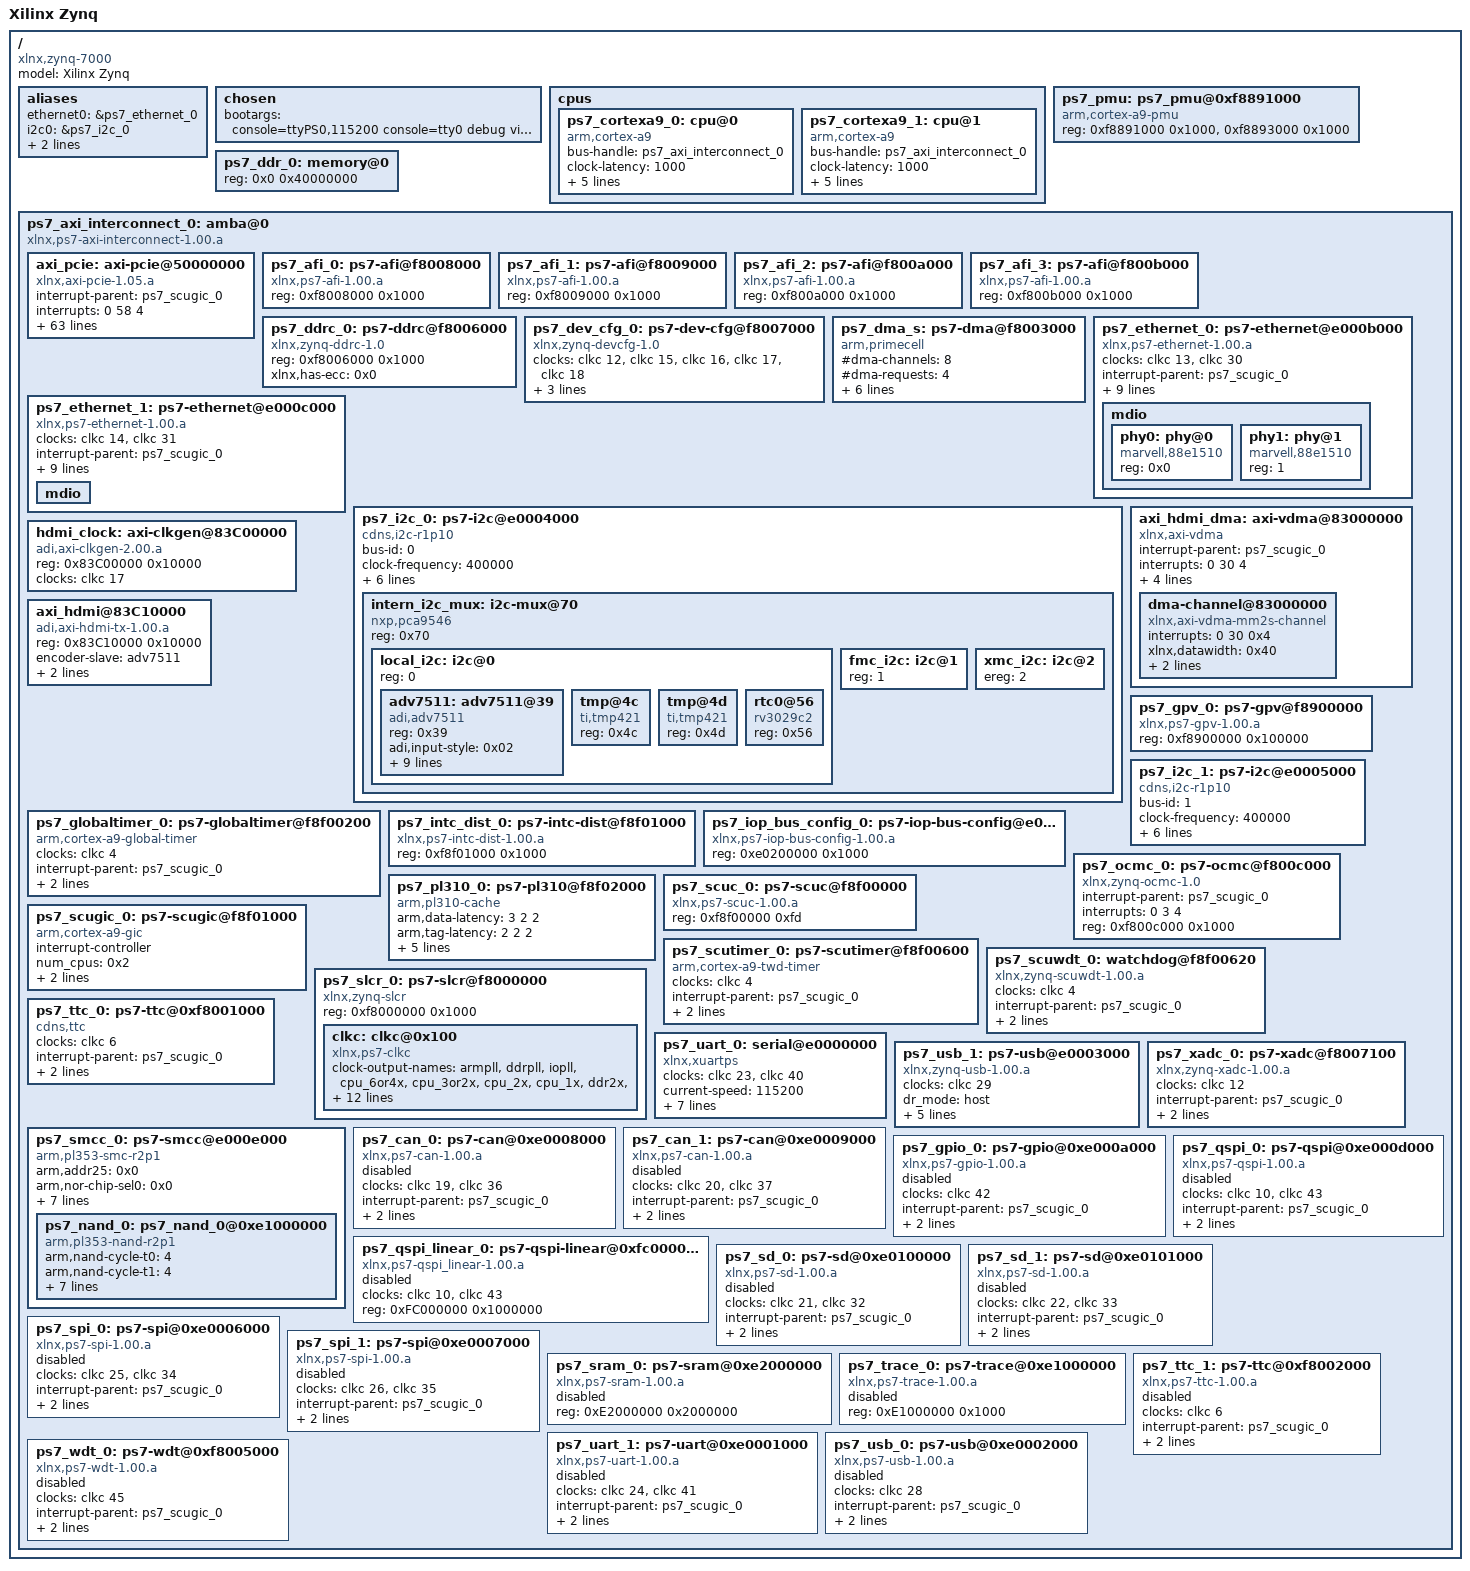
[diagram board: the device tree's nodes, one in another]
/*
 *  ApisSys AV108 Device Tree
 *  2014.2 Release 
 *
 */

/dts-v1/;
/ {
	#address-cells = <1>;
	#size-cells = <1>;
	compatible = "xlnx,zynq-7000";
	model = "Xilinx Zynq";
	aliases {
		ethernet0 = &ps7_ethernet_0;
		/*ethernet1 = &ps7_ethernet_1;*/
		i2c0 = &ps7_i2c_0;
		i2c1 = &ps7_i2c_1;
		serial0 = &ps7_uart_0;
	} ;
	chosen {
	    bootargs = "console=ttyPS0,115200 console=tty0 debug video=HDMI-A-1:1920x1080 vmalloc=384M root=/dev/ram rw ip=:::::eth0:dhcp earlyprintk ;linux,stdout-path =  /amba@0/serial@e0000000 ;";
	};

	cpus {
		#address-cells = <0x1>;
		#size-cells = <0x0>;
		ps7_cortexa9_0: cpu@0 {
			bus-handle = <&ps7_axi_interconnect_0>;
			clock-latency = <1000>;
			clocks = <&clkc 3>;
			compatible = "arm,cortex-a9";
			device_type = "cpu";
			interrupt-handle = <&ps7_scugic_0>;
			operating-points = <666667 1000000 333334 1000000 222223 1000000>;
			reg = <0x0>;
		};

		ps7_cortexa9_1: cpu@1 {
			bus-handle = <&ps7_axi_interconnect_0>;
			clock-latency = <1000>;
			clocks = <&clkc 3>;
			compatible = "arm,cortex-a9";
			device_type = "cpu";
			interrupt-handle = <&ps7_scugic_0>;
			operating-points = <666667 1000000 333334 1000000 222223 1000000>;
			reg = <0x1>;
		};
	};

	ps7_pmu: ps7_pmu@0xf8891000 {
		compatible = "arm,cortex-a9-pmu";
		reg = <0xf8891000 0x1000>, <0xf8893000 0x1000>;
		reg-names = "cpu0", "cpu1";
	};
	ps7_ddr_0: memory@0 {
		device_type = "memory";
		reg = <0x0 0x40000000>;
	};
	ps7_axi_interconnect_0: amba@0 {
		#address-cells = <0x1>;
		#size-cells = <0x1>;
		compatible = "xlnx,ps7-axi-interconnect-1.00.a", "simple-bus";
		ranges;
		linux,phandle = <0x1>;
		phandle = <0x1>;

		axi_pcie: axi-pcie@50000000 {
			#address-cells = <3>;		// Added from previous dts 
			#size-cells = <2>;		// Addes from previous dts 
			compatible = "xlnx,axi-pcie-1.05.a";
			ranges = <0x2000000 0x0 0x60000000 0x60000000 0x0 0x10000000>; // Added from previous dts 
			interrupt-parent = <&ps7_scugic_0>;
			interrupts = <0 58 4>;
			reg = <0x50000000 0x1000000>;
			//, <0x60000000 0x10000000>;
			xlnx,axibar-0 = <0x60000000>;
			xlnx,axibar-1 = <0xFFFFFFFF>;
			xlnx,axibar-2 = <0xFFFFFFFF>;
			xlnx,axibar-3 = <0xFFFFFFFF>;
			xlnx,axibar-4 = <0xFFFFFFFF>;
			xlnx,axibar-5 = <0xFFFFFFFF>;
			xlnx,axibar-as-0 = <0x0>;
			xlnx,axibar-as-1 = <0x0>;
			xlnx,axibar-as-2 = <0x0>;
			xlnx,axibar-as-3 = <0x0>;
			xlnx,axibar-as-4 = <0x0>;
			xlnx,axibar-as-5 = <0x0>;
			xlnx,axibar-highaddr-0 = <0x6FFFFFFF>;
			xlnx,axibar-highaddr-1 = <0x00000000>;
			xlnx,axibar-highaddr-2 = <0x00000000>;
			xlnx,axibar-highaddr-3 = <0x00000000>;
			xlnx,axibar-highaddr-4 = <0x00000000>;
			xlnx,axibar-highaddr-5 = <0x00000000>;
			xlnx,axibar-num = <0x1>;
			xlnx,axibar2pciebar-0 = <0x60000000>;
			xlnx,axibar2pciebar-1 = <0x00000000>;
			xlnx,axibar2pciebar-2 = <0x00000000>;
			xlnx,axibar2pciebar-3 = <0x00000000>;
			xlnx,axibar2pciebar-4 = <0x00000000>;
			xlnx,axibar2pciebar-5 = <0x00000000>;
			xlnx,class-code = <0x060400>;
			xlnx,comp-timeout = <0x1>;
			xlnx,device = "xc7z045";
			xlnx,device-id = <0x0706>;
			xlnx,include-baroffset-reg = <0x1>;
			xlnx,include-rc = <0x1>;
			xlnx,interrupt-pin = <0x0>;
			xlnx,max-link-speed = <0x0>;
			xlnx,no-of-lanes = <0x4>;
			xlnx,num-msi-req = <0x0>;
			xlnx,pcie-blk-locn = <0x0>;
			xlnx,pcie-cap-slot-implemented = <0x0>;
			xlnx,pcie-use-mode = "3.0";
			xlnx,pciebar-as = <0x0>;
			xlnx,pciebar-len-0 = <0x1e>;
			xlnx,pciebar-len-1 = <0x10>;
			xlnx,pciebar-len-2 = <0x10>;
			xlnx,pciebar-num = <0x1>;
			xlnx,pciebar2axibar-0 = <0x00000000>;
			xlnx,pciebar2axibar-0-sec = <0x1>;
			xlnx,pciebar2axibar-1 = <0xFFFFFFFF>;
			xlnx,pciebar2axibar-1-sec = <0x1>;
			xlnx,pciebar2axibar-2 = <0xFFFFFFFF>;
			xlnx,pciebar2axibar-2-sec = <0x1>;
			xlnx,ref-clk-freq = <0x0>;
			xlnx,rev-id = <0x0>;
			xlnx,s-axi-ctl-aclk-freq-hz = <0x7735940>;
			xlnx,s-axi-ctl-protocol = "AXI4LITE";
			xlnx,s-axi-id-width = <0xc>;
			xlnx,s-axi-support-threads = <0x1>;
			xlnx,s-axi-supports-narrow-burst = <0x1>;
			xlnx,s-axi-supports-read = <0x1>;
			xlnx,s-axi-supports-write = <0x1>;
			xlnx,subsystem-id = <0x0007>;
			xlnx,subsystem-vendor-id = <0x10EE>;
			xlnx,vendor-id = <0x10EE>;
			xlnx,xlnx-ref-board = "NONE";
		} ;


		ps7_afi_0: ps7-afi@f8008000 {
			compatible = "xlnx,ps7-afi-1.00.a";
			reg = <0xf8008000 0x1000>;
		};

		ps7_afi_1: ps7-afi@f8009000 {
			compatible = "xlnx,ps7-afi-1.00.a";
			reg = <0xf8009000 0x1000>;
		};

		ps7_afi_2: ps7-afi@f800a000 {
			compatible = "xlnx,ps7-afi-1.00.a";
			reg = <0xf800a000 0x1000>;
		};

		ps7_afi_3: ps7-afi@f800b000 {
			compatible = "xlnx,ps7-afi-1.00.a";
			reg = <0xf800b000 0x1000>;
		};

/*
		ps7_coresight_comp_0: ps7-coresight-comp@f8800000 {
			compatible = "xlnx,ps7-coresight-comp-1.00.a";
			reg = <0xf8800000 0x100000>;
		};
*/

		ps7_ddrc_0: ps7-ddrc@f8006000 {
			compatible = "xlnx,zynq-ddrc-1.0";
			reg = <0xf8006000 0x1000>;
			xlnx,has-ecc = <0x0>;
		};
		ps7_dev_cfg_0: ps7-dev-cfg@f8007000 {
			clock-names = "ref_clk", "fclk0", "fclk1", "fclk2", "fclk3";
			clocks = <&clkc 12>, <&clkc 15>, <&clkc 16>, <&clkc 17>, <&clkc 18>;
			compatible = "xlnx,zynq-devcfg-1.0";
			interrupt-parent = <&ps7_scugic_0>;
			interrupts = <0 8 4>;
			reg = <0xf8007000 0x100>;
		};

		ps7_dma_s: ps7-dma@f8003000 {
			#dma-cells = <1>;
			#dma-channels = <8>;
			#dma-requests = <4>;
			arm,primecell-periphid = <0x00041330>;
			clock-names = "apb_pclk";
			clocks = <&clkc 27>;
			compatible = "arm,primecell", "arm,pl330";
			interrupt-names = "abort", "dma0", "dma1", "dma2", "dma3", "dma4", "dma5", "dma6", "dma7";
			interrupt-parent = <&ps7_scugic_0>;
			interrupts = <0 13 4>, <0 14 4>, <0 15 4>, <0 16 4>, <0 17 4>, <0 40 4>, <0 41 4>, <0 42 4>, <0 43 4>;
			reg = <0xf8003000 0x1000>;
		};

		ps7_ethernet_0: ps7-ethernet@e000b000 {
			#address-cells = <1>;
			#size-cells = <0>;
			clock-names = "ref_clk", "aper_clk";
			clocks = <&clkc 13>, <&clkc 30>;
			compatible = "xlnx,ps7-ethernet-1.00.a";
			interrupt-parent = <&ps7_scugic_0>;
			interrupts = <0 22 4>;
			local-mac-address = [00 0a 35 00 00 00];
			phy-handle = <&phy0>;
			phy-mode = "rgmii-id";
			reg = <0xe000b000 0x1000>;
			xlnx,ptp-enet-clock = <0x69f6bcb>;
			xlnx,enet-reset = "";
			xlnx,eth-mode = <0x1>;
			xlnx,has-mdio = <0x1>;
			mdio {
				#address-cells = <1>;
				#size-cells = <0>;
				phy0: phy@0 {
					compatible = "marvell,88e1510";
					device_type = "ethernet-phy";
					reg = <0x0>;
				};
				
				phy1: phy@1 {
					compatible = "marvell,88e1510";
					device_type = "ethernet-phy";
					reg = <1>;
				} ;
				
			};
		};


		ps7_ethernet_1: ps7-ethernet@e000c000 {
			#address-cells = <1>;
			#size-cells = <0>;
			clock-names = "ref_clk", "aper_clk";
			clocks = <&clkc 14>, <&clkc 31>;
			compatible = "xlnx,ps7-ethernet-1.00.a";
			interrupt-parent = <&ps7_scugic_0>;
			interrupts = <0 45 4>;
			local-mac-address = [00 0a 35 00 00 01];
			phy-handle = <&phy1>;
			phy-mode = "rgmii-id";
			reg = <0xe000c000 0x1000>;
			xlnx,ptp-enet-clock = <0x69f6bcb>;
			xlnx,enet-reset = "<Select>";
			xlnx,eth-mode = <0x1>;
			xlnx,has-mdio = <0x0>;
			mdio {
				#address-cells = <1>;
				#size-cells = <0>;
			} ;
		} ;


		ps7_i2c_0: ps7-i2c@e0004000 {
			bus-id = <0>;
			clock-frequency = <400000>;
			clocks = <&clkc 38>;
			compatible = "cdns,i2c-r1p10";
			interrupt-parent = <&ps7_scugic_0>;
			interrupts = <0 25 4>;
			reg = <0xe0004000 0x1000>;
			xlnx,has-interrupt = <0x1>;
			xlnx,i2c-reset = "";
			
			intern_i2c_mux: i2c-mux@70 {
				compatible = "nxp,pca9546";
				reg = <0x70>;
				#address-cells = <1>;
				#size-cells = <0>;
				
				local_i2c: i2c@0 {
				      #address-cells = <1>;
				      #size-cells = <0>;
				      reg = <0>;
				      
				      adv7511: adv7511@39 {
					      compatible = "adi,adv7511";
					      reg = <0x39>;
					      adi,input-style = <0x02>;
					      adi,input-id = <0x01>;
					      adi,input-color-depth = <0x3>;
					      adi,sync-pulse = <0x00>;
					      adi,bit-justification = <0x00>;
					      adi,up-conversion = <0x00>;
					      adi,timing-generation-sequence = <0x00>;
					      adi,vsync-polarity = <0x02>;
					      adi,hsync-polarity = <0x02>;
					      adi,clock-delay = <0x03>;
					      /*adi,tdms-clock-inversion;*/
				      };
				
				      tmp@4c {
						compatible = "ti,tmp421";
						reg = <0x4c>;
				      };
				      tmp@4d {
						compatible = "ti,tmp421";
						reg = <0x4d>;
				      };               
				      rtc0@56 {
					      compatible = "rv3029c2";
					      reg = <0x56>;
				      };
				};      
				fmc_i2c: i2c@1 {
				      #address-cells = <1>;
				      #size-cells = <0>;
				      reg = <1>;
				};
				xmc_i2c: i2c@2 {
				      #address-cells = <1>;
				      #size-cells = <0>;
				      ereg = <2>;
				};         
			};	
		} ;

		axi_hdmi_dma: axi-vdma@83000000 {
			compatible = "xlnx,axi-vdma";
			interrupt-parent = <&ps7_scugic_0>;
			interrupts = <0 30 4>;
			#address-cells = <1>;
			#size-cells = <1>;
			#dma-cells = <1>;
			#dma-channels = <1>;
			reg = <0x83000000 0x10000>;
			xlnx,include-sg = <0x0>;
			xlnx,num-fstores = <0x3>;
			dma-channel@83000000 {
				compatible = "xlnx,axi-vdma-mm2s-channel";
				interrupts = <0 30 0x4>;
				xlnx,datawidth = <0x40>;
				xlnx,genlock-mode = <0x0>;
				xlnx,include-dre = <0x0>;
			};
		} ;
		
		/*	
		
		xlnx,dlytmr-resolution = <0x7d>;
		xlnx,dynamic-resolution = <0x1>;
		xlnx,enable-debug-all = <0x0>;
		xlnx,enable-debug-info-0 = <0x0>;
		xlnx,enable-debug-info-1 = <0x0>;
		xlnx,enable-debug-info-10 = <0x0>;
		xlnx,enable-debug-info-11 = <0x0>;
		xlnx,enable-debug-info-12 = <0x0>;
		xlnx,enable-debug-info-13 = <0x0>;
		xlnx,enable-debug-info-14 = <0x1>;
		xlnx,enable-debug-info-15 = <0x1>;
		xlnx,enable-debug-info-2 = <0x0>;
		xlnx,enable-debug-info-3 = <0x0>;
		xlnx,enable-debug-info-4 = <0x0>;
		xlnx,enable-debug-info-5 = <0x0>;
		xlnx,enable-debug-info-6 = <0x1>;
		xlnx,enable-debug-info-7 = <0x1>;
		xlnx,enable-debug-info-8 = <0x0>;
		xlnx,enable-debug-info-9 = <0x0>;
		xlnx,enable-vidprmtr-reads = <0x1>;
		xlnx,flush-on-fsync = <0x1>;
		xlnx,include-internal-genlock = <0x1>;
		xlnx,include-mm2s = <0x1>;
		xlnx,include-mm2s-dre = <0x0>;
		xlnx,include-mm2s-sf = <0x0>;
		xlnx,include-s2mm = <0x0>;
		xlnx,include-s2mm-dre = <0x0>;
		xlnx,include-s2mm-sf = <0x1>;
		xlnx,include-sg = <0x0>;
		xlnx,mm2s-genlock-mode = <0x3>;
		xlnx,mm2s-genlock-num-masters = <0x1>;
		xlnx,mm2s-genlock-repeat-en = <0x0>;
		xlnx,mm2s-linebuffer-depth = <0x200>;
		xlnx,mm2s-linebuffer-thresh = <0x4>;
		xlnx,mm2s-max-burst-length = <0x8>;
		xlnx,mm2s-sof-enable = <0x1>;
		xlnx,num-fstores = <0x3>;
		xlnx,prmry-is-aclk-async = <0x0>;
		xlnx,s2mm-genlock-mode = <0x0>;
		xlnx,s2mm-genlock-num-masters = <0x1>;
		xlnx,s2mm-genlock-repeat-en = <0x1>;
		xlnx,s2mm-linebuffer-depth = <0x200>;
		xlnx,s2mm-linebuffer-thresh = <0x4>;
		xlnx,s2mm-max-burst-length = <0x8>;
		xlnx,s2mm-sof-enable = <0x1>;
		xlnx,use-fsync = <0x1>;
		xlnx,use-mm2s-fsync = <0x1>;
		xlnx,use-s2mm-fsync = <0x2>;
		
		axi_vdma_0: axivdma@83000000 {
			compatible = "xlnx,axi-vdma";
			#address-cells = <1>;
			#size-cells = <1>;
			#dma-cells = <1>;
			#dma-channels = <1>;
			reg = <0x83000000 0x1000>;
			xlnx,include-sg = <0x0>;
			xlnx,num-fstores = <0x3>;
			dma-channel@83000000 {
				compatible = "xlnx,axi-vdma-mm2s-channel";
				interrupts = <0 29 0x4>;
				xlnx,datawidth = <0x40>;
				xlnx,genlock-mode = <0x0>;
				xlnx,include-dre = <0x0>;
			};
		};
		*/

		hdmi_clock: axi-clkgen@83C00000 {
			compatible = "adi,axi-clkgen-2.00.a";
			reg = <0x83C00000 0x10000>;
			#clock-cells = <0>;
			clocks = <&clkc 17>;
		};

		axi_hdmi@83C10000 {
			compatible = "adi,axi-hdmi-tx-1.00.a";
			reg = <0x83C10000 0x10000>;
			encoder-slave = <&adv7511>;
			dmas = <&axi_hdmi_dma 0>;
			dma-names = "video";
			clocks = <&hdmi_clock>;
		};
		
		
		ps7_globaltimer_0: ps7-globaltimer@f8f00200 {
			clocks = <&clkc 4>;
			compatible = "arm,cortex-a9-global-timer";
			interrupt-parent = <&ps7_scugic_0>;
			interrupts = <1 11 0x301>;
			reg = <0xf8f00200 0x100>;
		};

		ps7_gpv_0: ps7-gpv@f8900000 {
			compatible = "xlnx,ps7-gpv-1.00.a";
			reg = <0xf8900000 0x100000>;
		};

		
		
		ps7_i2c_1: ps7-i2c@e0005000 {
			bus-id = <1>;
			clock-frequency = <400000>;
			clocks = <&clkc 39>;
			compatible = "cdns,i2c-r1p10";
			interrupt-parent = <&ps7_scugic_0>;
			interrupts = <0 48 4>;
			reg = <0xe0005000 0x1000>;
			xlnx,has-interrupt = <0x1>;
			xlnx,i2c-reset = "<Select>";
		} ;
		ps7_intc_dist_0: ps7-intc-dist@f8f01000 {
			compatible = "xlnx,ps7-intc-dist-1.00.a";
			reg = <0xf8f01000 0x1000>;
		} ;
		ps7_iop_bus_config_0: ps7-iop-bus-config@e0200000 {
			compatible = "xlnx,ps7-iop-bus-config-1.00.a";
			reg = <0xe0200000 0x1000>;
		};

/*
		ps7_l2cachec_0: ps7-l2cachec@f8f02000 {
			compatible = "xlnx,ps7-l2cachec-1.00.a";
			reg = <0xf8f02000 0x1000>;
		};
*/

		ps7_ocmc_0: ps7-ocmc@f800c000 {
			compatible = "xlnx,zynq-ocmc-1.0";
			interrupt-parent = <&ps7_scugic_0>;
			interrupts = <0 3 4>;
			reg = <0xf800c000 0x1000>;
		};

		ps7_pl310_0: ps7-pl310@f8f02000 {
			arm,data-latency = <3 2 2>;
			arm,tag-latency = <2 2 2>;
			cache-level = <2>;
			cache-unified ;
			compatible = "arm,pl310-cache";
			interrupt-parent = <&ps7_scugic_0>;
			interrupts = <0 2 4>;
			reg = <0xf8f02000 0x1000>;
		};
		ps7_scuc_0: ps7-scuc@f8f00000 {
			compatible = "xlnx,ps7-scuc-1.00.a";
			reg = <0xf8f00000 0xfd>;
		} ;

		ps7_scugic_0: ps7-scugic@f8f01000 {
			#address-cells = <0x2>;
			#interrupt-cells = <0x3>;
			#size-cells = <0x1>;
			compatible = "arm,cortex-a9-gic", "arm,gic";
			interrupt-controller ;
			num_cpus = <0x2>;
			num_interrupts = <0x60>;
			reg = <0xf8f01000 0x1000 0xf8f00100 0x100>;
			/*xlnx,irq-f2p-mode = "DIRECT";*/
		};

		ps7_scutimer_0: ps7-scutimer@f8f00600 {
			clocks = <&clkc 4>;
			compatible = "arm,cortex-a9-twd-timer";
			interrupt-parent = <&ps7_scugic_0>;
			interrupts = <1 13 0x301>;
			reg = <0xf8f00600 0x20>;
		};

		ps7_scuwdt_0: watchdog@f8f00620 {
			clocks = <&clkc 4>;
			compatible = "xlnx,zynq-scuwdt-1.00.a";
			device_type = "watchdog";
			interrupt-parent = <&ps7_scugic_0>;
			interrupts = <1 14 0x301>;
			reg = <0xf8f00620 0xe0>;
		};

		ps7_slcr_0: ps7-slcr@f8000000 {
			#address-cells = <1>;
			#size-cells = <1>;
			compatible = "xlnx,zynq-slcr", "syscon";
			ranges  ;
			reg = <0xf8000000 0x1000>;
			clkc: clkc@0x100 {
				#clock-cells = <1>;
				clock-output-names = "armpll", "ddrpll", "iopll", "cpu_6or4x", "cpu_3or2x", "cpu_2x", "cpu_1x", "ddr2x", "ddr3x", "dci", "lqspi", "smc", "pcap", "gem0", "gem1", "fclk0", "fclk1", "fclk2", "fclk3", "can0", "can1", "sdio0", "sdio1", "uart0", "uart1", "spi0", "spi1", "dma", "usb0_aper", "usb1_aper", "gem0_aper", "gem1_aper", "sdio0_aper", "sdio1_aper", "spi0_aper", "spi1_aper", "can0_aper", "can1_aper", "i2c0_aper", "i2c1_aper", "uart0_aper", "uart1_aper", "gpio_aper", "lqspi_aper", "smc_aper", "swdt", "dbg_trc", "dbg_apb";
				compatible = "xlnx,ps7-clkc";
				fclk-enable = <0xf>;
				ps-clk-frequency = <33333333>;
				reg = <0x100 0x100>;
			};
		};


		ps7_ttc_0: ps7-ttc@0xf8001000 {
			clocks = <&clkc 6>;
			compatible = "cdns,ttc";
			interrupt-parent = <&ps7_scugic_0>;
			interrupts = <0 10 4>, <0 11 4>, <0 12 4>;
			reg = <0xf8001000 0x1000>;
		};

		ps7_uart_0: serial@e0000000 {
			clock-names = "uart_clk", "pclk";
			clocks = <&clkc 23>, <&clkc 40>;
			compatible = "xlnx,xuartps";
			current-speed = <115200>;
			device_type = "serial";
			interrupt-parent = <&ps7_scugic_0>;
			interrupts = <0 27 4>;
			port-number = <1>;
			clock-frequency = <100000000>;
			xlnx,uart-clk-freq-hz = <100000000>;
			reg = <0xe0000000 0x1000>;
			xlnx,has-modem = <0x0>;
		};

		
		ps7_usb_1: ps7-usb@e0003000 {
			clocks = <&clkc 29>;
			compatible = "xlnx,zynq-usb-1.00.a";
			dr_mode = "host";
			interrupt-parent = <&ps7_scugic_0>;
			interrupts = <0 44 4>;
			phy_type = "ulpi";
			reg = <0xe0003000 0x1000>;
			xlnx,usb-reset = "<Select>";
		};

		ps7_xadc_0: ps7-xadc@f8007100 {
			clocks = <&clkc 12>;
			compatible = "xlnx,zynq-xadc-1.00.a";
			interrupt-parent = <&ps7_scugic_0>;
			interrupts = <0 7 4>;
			reg = <0xf8007100 0x21>;
		};
		ps7_smcc_0: ps7-smcc@e000e000 {
			#address-cells = <1>;
			#size-cells = <1>;
			arm,addr25 = <0x0>;
			arm,nor-chip-sel0 = <0x0>;
			arm,nor-chip-sel1 = <0x0>;
			arm,sram-chip-sel0 = <0x0>;
			arm,sram-chip-sel1 = <0x0>;
			clock-names = "memclk", "aclk";
			clocks = <&clkc 11>, <&clkc 44>;
			compatible = "arm,pl353-smc-r2p1";
			interrupt-parent = <&ps7_scugic_0>;
			interrupts = <0 18 4>;
			ranges ;
			reg = <0xe000e000 0x1000>;
			ps7_nand_0: ps7_nand_0@0xe1000000 {
				arm,nand-cycle-t0 = <4>;
				arm,nand-cycle-t1 = <4>;
				arm,nand-cycle-t2 = <1>;
				arm,nand-cycle-t3 = <2>;
				arm,nand-cycle-t4 = <2>;
				arm,nand-cycle-t5 = <2>;
				arm,nand-cycle-t6 = <4>;
				compatible = "arm,pl353-nand-r2p1";
				nand-bus-width = <8>;
				reg = <0xe1000000 0x1000000>;
			};
		};



		ps7_can_0: ps7-can@0xe0008000 {
			clock-names = "ref_clk", "aper_clk";
			clocks = <&clkc 19>, <&clkc 36>;
			compatible = "xlnx,ps7-can-1.00.a";
			interrupt-parent = <&ps7_scugic_0>;
			interrupts = <0 28 4>;
			reg = <0xE0008000 0x1000>;
			status = "disabled";
		} ;
		ps7_can_1: ps7-can@0xe0009000 {
			clock-names = "ref_clk", "aper_clk";
			clocks = <&clkc 20>, <&clkc 37>;
			compatible = "xlnx,ps7-can-1.00.a";
			interrupt-parent = <&ps7_scugic_0>;
			interrupts = <0 51 4>;
			reg = <0xE0009000 0x1>;
			status = "disabled";
		} ;
		ps7_gpio_0: ps7-gpio@0xe000a000 {
			clocks = <&clkc 42>;
			compatible = "xlnx,ps7-gpio-1.00.a";
			interrupt-parent = <&ps7_scugic_0>;
			interrupts = <0 20 4>;
			reg = <0xE000A000 0x1000>;
			status = "disabled";
		} ;
		ps7_qspi_0: ps7-qspi@0xe000d000 {
			clock-names = "ref_clk", "aper_clk";
			clocks = <&clkc 10>, <&clkc 43>;
			compatible = "xlnx,ps7-qspi-1.00.a";
			interrupt-parent = <&ps7_scugic_0>;
			interrupts = <0 19 4>;
			reg = <0xE000D000 0x1000>;
			status = "disabled";
		} ;
		ps7_qspi_linear_0: ps7-qspi-linear@0xfc000000 {
			clock-names = "ref_clk", "aper_clk";
			clocks = <&clkc 10>, <&clkc 43>;
			compatible = "xlnx,ps7-qspi_linear-1.00.a";
			reg = <0xFC000000 0x1000000>;
			status = "disabled";
		} ;
		ps7_sd_0: ps7-sd@0xe0100000 {
			clock-names = "ref_clk", "aper_clk";
			clocks = <&clkc 21>, <&clkc 32>;
			compatible = "xlnx,ps7-sd-1.00.a";
			interrupt-parent = <&ps7_scugic_0>;
			interrupts = <0 24 4>;
			reg = <0xE0100000 0x1000>;
			status = "disabled";
		} ;
		ps7_sd_1: ps7-sd@0xe0101000 {
			clock-names = "ref_clk", "aper_clk";
			clocks = <&clkc 22>, <&clkc 33>;
			compatible = "xlnx,ps7-sd-1.00.a";
			interrupt-parent = <&ps7_scugic_0>;
			interrupts = <0 47 4>;
			reg = <0xE0101000 0x1000>;
			status = "disabled";
		} ;
		ps7_spi_0: ps7-spi@0xe0006000 {
			clock-names = "ref_clk", "aper_clk";
			clocks = <&clkc 25>, <&clkc 34>;
			compatible = "xlnx,ps7-spi-1.00.a";
			interrupt-parent = <&ps7_scugic_0>;
			interrupts = <0 26 4>;
			reg = <0xE0006000 0x1000>;
			status = "disabled";
		} ;
		ps7_spi_1: ps7-spi@0xe0007000 {
			clock-names = "ref_clk", "aper_clk";
			clocks = <&clkc 26>, <&clkc 35>;
			compatible = "xlnx,ps7-spi-1.00.a";
			interrupt-parent = <&ps7_scugic_0>;
			interrupts = <0 49 4>;
			reg = <0xE0007000 0x1000>;
			status = "disabled";
		} ;
		ps7_sram_0: ps7-sram@0xe2000000 {
			compatible = "xlnx,ps7-sram-1.00.a";
			reg = <0xE2000000 0x2000000>;
			status = "disabled";
		} ;
		ps7_trace_0: ps7-trace@0xe1000000 {
			compatible = "xlnx,ps7-trace-1.00.a";
			reg = <0xE1000000 0x1000>;
			status = "disabled";
		} ;
		ps7_ttc_1: ps7-ttc@0xf8002000 {
			clocks = <&clkc 6>;
			compatible = "xlnx,ps7-ttc-1.00.a";
			interrupt-parent = <&ps7_scugic_0>;
			interrupts = <0 37 4>, <0 38 4>, <0 39 4>;
			reg = <0xF8002000 0x1000>;
			status = "disabled";
		} ;	
		ps7_uart_1: ps7-uart@0xe0001000 {
			clock-names = "uart_clk", "pclk";
			clocks = <&clkc 24>, <&clkc 41>;
			compatible = "xlnx,ps7-uart-1.00.a";
			interrupt-parent = <&ps7_scugic_0>;
			interrupts = <0 50 4>;
			reg = <0xE0001000 0x1000>;
			status = "disabled";
		} ;
		ps7_usb_0: ps7-usb@0xe0002000 {
			clocks = <&clkc 28>;
			compatible = "xlnx,ps7-usb-1.00.a";
			interrupt-parent = <&ps7_scugic_0>;
			interrupts = <0 21 4>;
			reg = <0xE0002000 0x1000>;
			status = "disabled";
		} ;
		ps7_wdt_0: ps7-wdt@0xf8005000 {
			clocks = <&clkc 45>;
			compatible = "xlnx,ps7-wdt-1.00.a";
			interrupt-parent = <&ps7_scugic_0>;
			interrupts = <0 9 1>;
			reg = <0xF8005000 0x1000>;
			status = "disabled";
		} ;
	};
};
